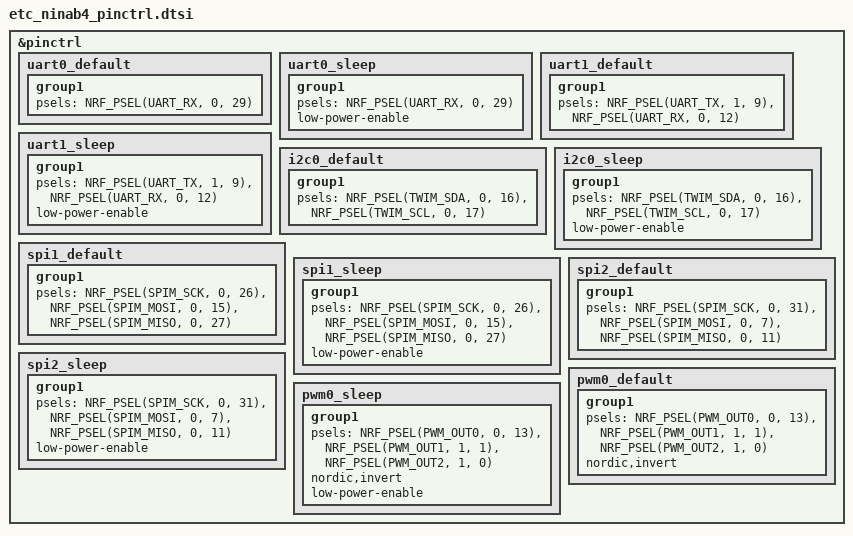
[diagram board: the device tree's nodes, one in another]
&pinctrl {
	uart0_default: uart0_default {
		group1 {
			psels = <NRF_PSEL(UART_RX, 0, 29)>;
		};
	};

	uart0_sleep: uart0_sleep {
		group1 {
			psels = <NRF_PSEL(UART_RX, 0, 29)>;
			low-power-enable;
		};
	};

	uart1_default: uart1_default {
		group1 {
			psels = <NRF_PSEL(UART_TX, 1, 9)>,
				<NRF_PSEL(UART_RX, 0, 12)>;
		};
	};

	uart1_sleep: uart1_sleep {
		group1 {
			psels = <NRF_PSEL(UART_TX, 1, 9)>,
				<NRF_PSEL(UART_RX, 0, 12)>;
			low-power-enable;
		};
	};

	i2c0_default: i2c0_default {
		group1 {
			psels = <NRF_PSEL(TWIM_SDA, 0, 16)>,
				<NRF_PSEL(TWIM_SCL, 0, 17)>;
		};
	};

	i2c0_sleep: i2c0_sleep {
		group1 {
			psels = <NRF_PSEL(TWIM_SDA, 0, 16)>,
				<NRF_PSEL(TWIM_SCL, 0, 17)>;
				low-power-enable;
		};
	};

	spi1_default: spi1_default {
		group1 {
			psels = <NRF_PSEL(SPIM_SCK, 0, 26)>,
				<NRF_PSEL(SPIM_MOSI, 0, 15)>,
				<NRF_PSEL(SPIM_MISO, 0, 27)>;
		};
	};

	spi1_sleep: spi1_sleep {
		group1 {
			psels = <NRF_PSEL(SPIM_SCK, 0, 26)>,
				<NRF_PSEL(SPIM_MOSI, 0, 15)>,
				<NRF_PSEL(SPIM_MISO, 0, 27)>;
			low-power-enable;
		};
	};

	spi2_default: spi2_default {
		group1 {
			psels = <NRF_PSEL(SPIM_SCK, 0, 31)>,
				<NRF_PSEL(SPIM_MOSI, 0, 7)>,
				<NRF_PSEL(SPIM_MISO, 0, 11)>;
		};
	};

	spi2_sleep: spi2_sleep {
		group1 {
			psels = <NRF_PSEL(SPIM_SCK, 0, 31)>,
				<NRF_PSEL(SPIM_MOSI, 0, 7)>,
				<NRF_PSEL(SPIM_MISO, 0, 11)>;
			low-power-enable;
		};
	};

	pwm0_default: pwm0_default {
		group1 {
			psels = <NRF_PSEL(PWM_OUT0, 0, 13)>,
				<NRF_PSEL(PWM_OUT1, 1, 1)>,
				<NRF_PSEL(PWM_OUT2, 1, 0)>;
				nordic,invert;
		};
	};

	pwm0_sleep: pwm0_sleep {
		group1 {
			psels = <NRF_PSEL(PWM_OUT0, 0, 13)>,
				<NRF_PSEL(PWM_OUT1, 1, 1)>,
				<NRF_PSEL(PWM_OUT2, 1, 0)>;
				nordic,invert;
				low-power-enable;
		};
	};
};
